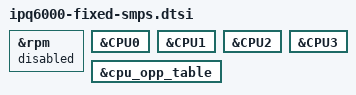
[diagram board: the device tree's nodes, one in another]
// SPDX-License-Identifier: GPL-2.0-only

/*
 * Board does not use companion MP5496 PMIC,
 * but rather uses fixed external SMPS.
 */

&rpm {
	status = "disabled";
};

&CPU0 {
	/delete-property/ cpu-supply;
};

&CPU1 {
	/delete-property/ cpu-supply;
};

&CPU2 {
	/delete-property/ cpu-supply;
};

&CPU3 {
	/delete-property/ cpu-supply;
};

&cpu_opp_table {
	/delete-node/ opp-1608000000;
	/delete-node/ opp-1800000000;
};
